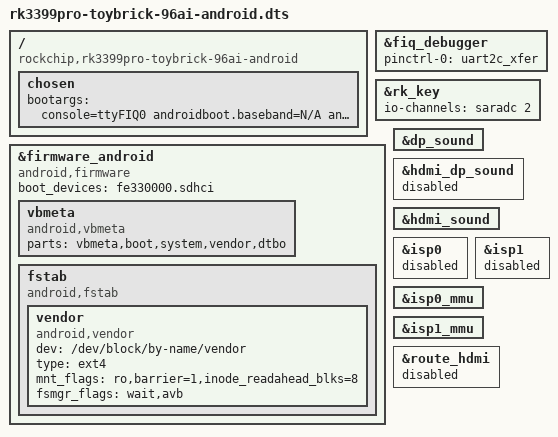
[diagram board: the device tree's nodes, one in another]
/*
 * Copyright (c) 2019 Fuzhou Rockchip Electronics Co., Ltd
 *
 * This file is dual-licensed: you can use it either under the terms
 * of the GPL or the X11 license, at your option. Note that this dual
 * licensing only applies to this file, and not this project as a
 * whole.
 *
 *  a) This file is free software; you can redistribute it and/or
 *     modify it under the terms of the GNU General Public License as
 *     published by the Free Software Foundation; either version 2 of the
 *     License, or (at your option) any later version.
 *
 *     This file is distributed in the hope that it will be useful,
 *     but WITHOUT ANY WARRANTY; without even the implied warranty of
 *     MERCHANTABILITY or FITNESS FOR A PARTICULAR PURPOSE.  See the
 *     GNU General Public License for more details.
 *
 * Or, alternatively,
 *
 *  b) Permission is hereby granted, free of charge, to any person
 *     obtaining a copy of this software and associated documentation
 *     files (the "Software"), to deal in the Software without
 *     restriction, including without limitation the rights to use,
 *     copy, modify, merge, publish, distribute, sublicense, and/or
 *     sell copies of the Software, and to permit persons to whom the
 *     Software is furnished to do so, subject to the following
 *     conditions:
 *
 *     The above copyright notice and this permission notice shall be
 *     included in all copies or substantial portions of the Software.
 *
 *     THE SOFTWARE IS PROVIDED "AS IS", WITHOUT WARRANTY OF ANY KIND,
 *     EXPRESS OR IMPLIED, INCLUDING BUT NOT LIMITED TO THE WARRANTIES
 *     OF MERCHANTABILITY, FITNESS FOR A PARTICULAR PURPOSE AND
 *     NONINFRINGEMENT. IN NO EVENT SHALL THE AUTHORS OR COPYRIGHT
 *     HOLDERS BE LIABLE FOR ANY CLAIM, DAMAGES OR OTHER LIABILITY,
 *     WHETHER IN AN ACTION OF CONTRACT, TORT OR OTHERWISE, ARISING
 *     FROM, OUT OF OR IN CONNECTION WITH THE SOFTWARE OR THE USE OR
 *     OTHER DEALINGS IN THE SOFTWARE.
 */

/dts-v1/;
#include "rk3399pro-toybrick-96ai.dtsi"
#include "rk3399-android.dtsi"

/ {
	compatible = "rockchip,rk3399pro-toybrick-96ai-android","rockchip,rk3399pro";

	chosen {
		bootargs = "console=ttyFIQ0 androidboot.baseband=N/A androidboot.wificountrycode=US androidboot.veritymode=enforcing androidboot.hardware=rk30board androidboot.console=ttyFIQ0 firmware_class.path=/vendor/etc/firmware init=/init rootwait ro init=/init androidboot.selinux=permissive";
	};
};

&fiq_debugger {
	pinctrl-0 = <&uart2c_xfer>;
};

&rk_key {
	status = "okay";
	io-channels = <&saradc 2>;
	/delete-node/ power-key;
};

&firmware_android {
	compatible = "android,firmware";
	boot_devices = "fe330000.sdhci";
	vbmeta {
		compatible = "android,vbmeta";
		parts = "vbmeta,boot,system,vendor,dtbo";
	};
	fstab {
		compatible = "android,fstab";
		vendor {
			compatible = "android,vendor";
			dev = "/dev/block/by-name/vendor";
			type = "ext4";
			mnt_flags = "ro,barrier=1,inode_readahead_blks=8";
			fsmgr_flags = "wait,avb";
		};
	};
};

&dp_sound {
	status = "okay";
};

&hdmi_dp_sound {
	status = "disabled";
};

&hdmi_sound {
	status = "okay";
};

&isp0 {
	status = "disabled";
};

&isp1 {
	status = "disabled";
};

&isp0_mmu {
	status = "okay";
};

&isp1_mmu {
	status = "okay";
};

&route_hdmi {
	status = "disabled";
};
